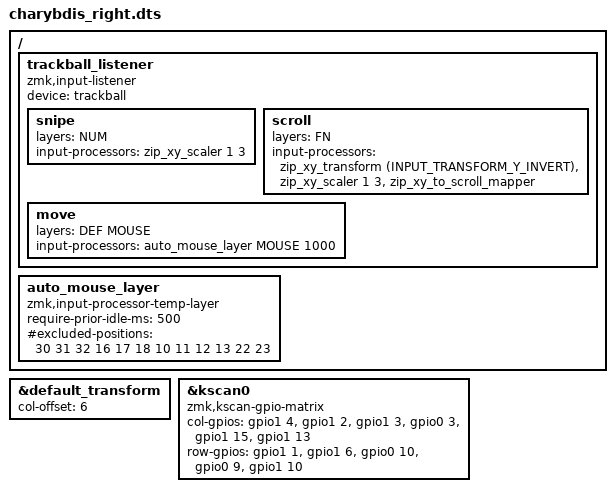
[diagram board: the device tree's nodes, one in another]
/*
 * Copyright (c) 2021 The ZMK Contributors
 *
 * SPDX-License-Identifier: MIT
 */

/dts-v1/;
#include <nordic/nrf52840_qiaa.dtsi>
#include "charybdis.dtsi"
#include "charybdis_pmw3610.dtsi"
#include <dt-bindings/zmk/input_transform.h>
#include <input/processors.dtsi>
#include "charybdis_layers.h"

&default_transform {
	col-offset = <6>;
};

&kscan0 {
    compatible = "zmk,kscan-gpio-matrix";

    col-gpios
        = <&gpio1 4   (GPIO_ACTIVE_HIGH | GPIO_PULL_DOWN)>
        , <&gpio1 2   (GPIO_ACTIVE_HIGH | GPIO_PULL_DOWN)>
        , <&gpio1 3   (GPIO_ACTIVE_HIGH | GPIO_PULL_DOWN)>
        , <&gpio0 3   (GPIO_ACTIVE_HIGH | GPIO_PULL_DOWN)>
        , <&gpio1 15  (GPIO_ACTIVE_HIGH | GPIO_PULL_DOWN)>
        , <&gpio1 13  (GPIO_ACTIVE_HIGH | GPIO_PULL_DOWN)>
    ;
    row-gpios
        = <&gpio1 1   GPIO_ACTIVE_HIGH>
        , <&gpio1 6   GPIO_ACTIVE_HIGH>
        , <&gpio0 10  GPIO_ACTIVE_HIGH>
        , <&gpio0 9   GPIO_ACTIVE_HIGH>
        , <&gpio1 10  GPIO_ACTIVE_HIGH>
    ;
};

/ {
  trackball_listener: trackball_listener {
    compatible = "zmk,input-listener";
    device = <&trackball>;
    status = "okay";

    snipe {
      layers = <NUM>;
      input-processors = <&zip_xy_scaler 1 3>;
    };

    scroll {
      layers = <FN>;
      input-processors = <&zip_xy_transform (INPUT_TRANSFORM_Y_INVERT)>, <&zip_xy_scaler 1 3>, <&zip_xy_to_scroll_mapper>;
    };

    move {
      layers = <DEF MOUSE>;
      input-processors = <&auto_mouse_layer MOUSE 1000>;
    };
  };

  auto_mouse_layer: auto_mouse_layer {
    compatible = "zmk,input-processor-temp-layer";
    #input-processor-cells = <2>;
    require-prior-idle-ms = <500>;
    #excluded-positions = <30 31 32 16 17 18 10 11 12 13 22 23>;
  };
};
